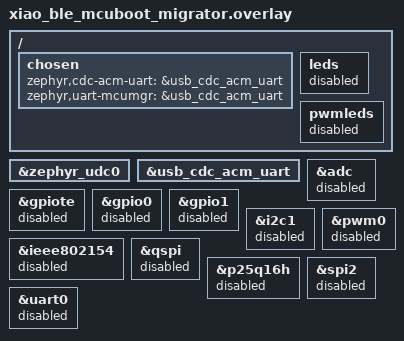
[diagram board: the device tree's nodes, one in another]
/*
 * fw2 MCUboot (Option B migrator path) board overlay -- mcuboot child image.
 * Mirrors the validated fw1 USB-CDC recovery overlay
 * (xiao_ble_mcuboot_usb_cdc_recovery.overlay): MCUboot's serial recovery uses
 * the CDC ACM UART so the empty-primary fw2 can receive the real app over USB.
 */

/ {
	chosen {
		zephyr,cdc-acm-uart = &usb_cdc_acm_uart;
		zephyr,uart-mcumgr = &usb_cdc_acm_uart;
	};

	leds {
		status = "disabled";
	};

	pwmleds {
		status = "disabled";
	};
};

&zephyr_udc0 {
	status = "okay";
};

/*
 * NCS 2.9.2 renamed the xiao_ble USB-CDC node label cdc_acm_uart0 ->
 * usb_cdc_acm_uart (xiao_ble_common.dtsi). The bootloader's serial recovery uses
 * this CDC UART (chosen above), so leave the board's usb_cdc_acm_uart enabled
 * rather than disabling it and pointing at a now-undefined cdc_acm_uart0.
 */
&usb_cdc_acm_uart {
	status = "okay";
};

&adc {
	status = "disabled";
};

&gpiote {
	status = "disabled";
};

&gpio0 {
	status = "disabled";
};

&gpio1 {
	status = "disabled";
};

&i2c1 {
	status = "disabled";
};

&ieee802154 {
	status = "disabled";
};

&pwm0 {
	status = "disabled";
};

&qspi {
	status = "disabled";
};

&p25q16h {
	status = "disabled";
};

&spi2 {
	status = "disabled";
};

&uart0 {
	status = "disabled";
};
